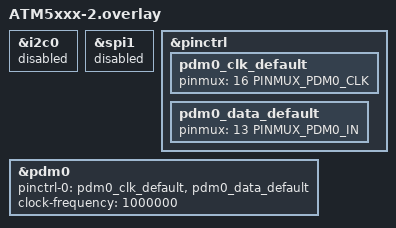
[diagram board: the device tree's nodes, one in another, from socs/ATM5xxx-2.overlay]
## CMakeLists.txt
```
# Copyright (c) 2026 Atmosic
#
# SPDX-License-Identifier: LicenseRef-Atmosic

cmake_minimum_required(VERSION 3.20.0)

find_package(Zephyr REQUIRED HINTS $ENV{ZEPHYR_BASE})
project(dmic_atm)

target_sources(app PRIVATE src/main.c)
```

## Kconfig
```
# Copyright (c) 2026 Atmosic
#
# SPDX-License-Identifier: LicenseRef-Atmosic

mainmenu "DMIC Sample"

source "Kconfig.zephyr"

choice SAMPLE_RATE_CHOICE
	prompt "PCM sample rate"
	default SAMPLE_RATE_16KHZ
	help
	  PCM sample rate requested from the dmic_atm driver. The driver
	  (openair/drivers/audio/dmic_atm.c, rate_to_sel()) only supports
	  8000 Hz and 16000 Hz.

config SAMPLE_RATE_8KHZ
	bool "8 kHz"

config SAMPLE_RATE_16KHZ
	bool "16 kHz"

endchoice

config SAMPLE_RATE_HZ
	int
	default 8000 if SAMPLE_RATE_8KHZ
	default 16000 if SAMPLE_RATE_16KHZ

config HW_CHANNEL_INDEX
	int "Hardware controller index"
	default 0
	help
	  Selects the PDM hardware controller index passed to
	  dmic_build_channel_map().  0 selects pdm0.

config DMIC_BENCH_DURATION_S
	int "Bench-test streaming duration (seconds)"
	default 2
	range 1 5
	help
	  How long to stream PDM audio before stopping and dumping the
	  captured samples. Kept short because the whole run is dumped
	  as hex over the console after stopping, and that dump is far
	  slower than the capture.
```

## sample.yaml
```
# Copyright (c) 2026 Atmosic
#
# SPDX-License-Identifier: LicenseRef-Atmosic

sample:
  name: DMIC
common:
  tags:
    - drivers
  sysbuild: true
  depends_on:
    - pdm
  harness: console
  harness_config:
    type: one_line
    regex:
      - 'PDM_CAPTURE_END captured=\d+ dropped=\d+'
tests:
  samples.drivers.audio.dmic.atm: {}
  samples.drivers.audio.dmic.atm.apx: &apx_base
    harness: pytest
    timeout: 600
    harness_config:
      pytest_root: ["pytest"]
      fixture: apx525
  samples.drivers.audio.dmic.atm.apx.rate_8khz:
    <<: *apx_base
    extra_configs:
      - CONFIG_SAMPLE_RATE_8KHZ=y
    harness_config:
      pytest_root: ["pytest"]
      fixture: apx525
      pytest_args:
        - "--apx-sweep-freqs-hz=250,500,750"
  samples.drivers.audio.dmic.atm.apx.bitclk_500khz:
    <<: *apx_base
    extra_args:
      - EXTRA_DTC_OVERLAY_FILE="bitclk_500khz.overlay"
    harness_config:
      pytest_root: ["pytest"]
      fixture: apx525
      pytest_args:
        - "--apx-bit-clk-freq-hz=500000"
        - "--apx-sweep-freqs-hz=500"
  samples.drivers.audio.dmic.atm.apx.bitclk_2mhz:
    <<: *apx_base
    extra_args:
      - EXTRA_DTC_OVERLAY_FILE="bitclk_2mhz.overlay"
    harness_config:
      pytest_root: ["pytest"]
      fixture: apx525
      pytest_args:
        - "--apx-bit-clk-freq-hz=2000000"
        - "--apx-sweep-freqs-hz=500,1000,1500"
  samples.drivers.audio.dmic.atm.apx.bitclk_4mhz:
    <<: *apx_base
    extra_args:
      - EXTRA_DTC_OVERLAY_FILE="bitclk_4mhz.overlay"
    harness_config:
      pytest_root: ["pytest"]
      fixture: apx525
      pytest_args:
        - "--apx-bit-clk-freq-hz=4000000"
        - "--apx-sweep-freqs-hz=500,1000,1500"
```

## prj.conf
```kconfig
# Copyright (c) 2026 Atmosic
#
# SPDX-License-Identifier: LicenseRef-Atmosic

CONFIG_AUDIO=y
CONFIG_AUDIO_DMIC=y
CONFIG_DMIC_ATM=y

CONFIG_LOG=y

# Send printk straight to the console (bypass the deferred log ring buffer)
# so the bench-test PCM hex dump is not silently truncated.
CONFIG_LOG_PRINTK=n
```

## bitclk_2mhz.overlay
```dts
/*
 * Copyright (c) 2026 Atmosic
 *
 * SPDX-License-Identifier: LicenseRef-Atmosic
 */

&pdm0 {
	clock-frequency = <2000000>;
};
```

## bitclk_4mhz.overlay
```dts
/*
 * Copyright (c) 2026 Atmosic
 *
 * SPDX-License-Identifier: LicenseRef-Atmosic
 */

&pdm0 {
	clock-frequency = <4000000>;
};
```

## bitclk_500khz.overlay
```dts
/*
 * Copyright (c) 2026 Atmosic
 *
 * SPDX-License-Identifier: LicenseRef-Atmosic
 */

&pdm0 {
	clock-frequency = <500000>;
};
```

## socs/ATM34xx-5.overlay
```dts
/*
 * Copyright (c) 2026 Atmosic
 *
 * SPDX-License-Identifier: LicenseRef-Atmosic
 */

&spi1 {
	status = "disabled";
};

&pinctrl {
	pdm0_clk_default: pdm0_clk_default {
		pinmux = <20 PINMUX_PDM0_CLK>;
	};

	pdm0_data_default: pdm0_data_default {
		pinmux = <21 PINMUX_PDM0_IN>;
	};
};

dmic_dev: &pdm0 {
	status = "okay";
	pinctrl-0 = <&pdm0_clk_default &pdm0_data_default>;
	pinctrl-names = "default";
	clock-frequency = <1000000>;
};
```

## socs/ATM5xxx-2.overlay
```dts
/*
 * Copyright (c) 2026 Atmosic
 *
 * SPDX-License-Identifier: LicenseRef-Atmosic
 */

&i2c0 {
	status = "disabled";
};

&spi1 {
	status = "disabled";
};

&pinctrl {
	pdm0_clk_default: pdm0_clk_default {
		pinmux = <16 PINMUX_PDM0_CLK>;
	};

	pdm0_data_default: pdm0_data_default {
		pinmux = <13 PINMUX_PDM0_IN>;
	};
};

dmic_dev: &pdm0 {
	status = "okay";
	pinctrl-0 = <&pdm0_clk_default &pdm0_data_default>;
	pinctrl-names = "default";
	clock-frequency = <1000000>;
};
```

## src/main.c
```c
/*
 * Copyright (c) Atmosic 2026
 *
 * SPDX-License-Identifier: LicenseRef-Atmosic
 */

#include <stdint.h>
#include <string.h>

#include <zephyr/kernel.h>
#include <zephyr/sys/util.h>
#include <zephyr/audio/dmic.h>

#include <zephyr/logging/log.h>

LOG_MODULE_REGISTER(dmic_sample);

#define MAX_SAMPLE_RATE  CONFIG_SAMPLE_RATE_HZ
#define SAMPLE_BIT_WIDTH 16
#define PDM_CTL_IDX      CONFIG_HW_CHANNEL_INDEX
#define BYTES_PER_SAMPLE (SAMPLE_BIT_WIDTH / 8)
#define READ_TIMEOUT     1000

#define PDM_HW_CHUNK_WORDS   16
#define PDM_HW_CHUNK_SAMPLES (PDM_HW_CHUNK_WORDS * 2)
#define PDM_BLOCK_SIZE       (PDM_HW_CHUNK_SAMPLES * BYTES_PER_SAMPLE)

#define MAX_BLOCK_SIZE PDM_BLOCK_SIZE
#define BLOCK_COUNT    4
K_MEM_SLAB_DEFINE_STATIC(mem_slab, MAX_BLOCK_SIZE, BLOCK_COUNT, 4);

#define DMIC_BENCH_WARMUP_MS 1000
#define MAX_READ_FAILURES    50

#define CAP_SAMPLES (MAX_SAMPLE_RATE * CONFIG_DMIC_BENCH_DURATION_S)
static int16_t capture_buf[CAP_SAMPLES];

int main(void)
{
	const struct device *dmic_dev = DEVICE_DT_GET(DT_NODELABEL(dmic_dev));

	if (!device_is_ready(dmic_dev)) {
		LOG_ERR("DMIC not ready");
		return 0;
	}

	struct pcm_stream_cfg stream = {
		.pcm_width = SAMPLE_BIT_WIDTH,
		.mem_slab = &mem_slab,
	};
	struct dmic_cfg cfg = {
		.io =
			{
				.min_pdm_clk_freq = 1000000,
				.max_pdm_clk_freq = 4000000,
				.min_pdm_clk_dc = 40,
				.max_pdm_clk_dc = 60,
			},
		.streams = &stream,
		.channel =
			{
				.req_num_streams = 1,
				.req_num_chan = 1,
				.req_chan_map_lo =
					dmic_build_channel_map(0, PDM_CTL_IDX, PDM_CHAN_LEFT),
			},
	};
	cfg.streams[0].pcm_rate = MAX_SAMPLE_RATE;
	cfg.streams[0].block_size = PDM_BLOCK_SIZE;

	int ret = dmic_configure(dmic_dev, &cfg);
	if (ret < 0) {
		LOG_ERR("Configure failed: %d", ret);
		return 0;
	}

	ret = dmic_trigger(dmic_dev, DMIC_TRIGGER_START);
	if (ret < 0) {
		LOG_ERR("START failed: %d", ret);
		return 0;
	}

	uint32_t pcm_rate = cfg.streams[0].pcm_rate;
	uint32_t warmup_samples = (DMIC_BENCH_WARMUP_MS * pcm_rate) / 1000U;
	uint32_t failures = 0;

	for (uint32_t warmed = 0; warmed < warmup_samples;) {
		void *buf;
		uint32_t size;
		ret = dmic_read(dmic_dev, 0, &buf, &size, READ_TIMEOUT);
		if (ret < 0) {
			if (++failures >= MAX_READ_FAILURES) {
				LOG_ERR("Warm-up abort: %u failures", failures);
				break;
			}
			continue;
		}
		failures = 0;
		k_mem_slab_free(&mem_slab, buf);
		warmed += PDM_HW_CHUNK_SAMPLES;
	}

	LOG_INF("Bench streaming started");

	uint32_t cap =
		MIN(CONFIG_DMIC_BENCH_DURATION_S * pcm_rate, (uint32_t)ARRAY_SIZE(capture_buf));
	uint32_t captured = 0, dropped = 0;
	failures = 0;

	while (captured < cap) {
		void *buf;
		uint32_t size;
		ret = dmic_read(dmic_dev, 0, &buf, &size, READ_TIMEOUT);
		if (ret < 0) {
			dropped++;
			if (++failures >= MAX_READ_FAILURES) {
				break;
			}
			continue;
		}
		failures = 0;
		memcpy(&capture_buf[captured], buf, PDM_HW_CHUNK_SAMPLES * sizeof(capture_buf[0]));
		k_mem_slab_free(&mem_slab, buf);
		captured += PDM_HW_CHUNK_SAMPLES;
	}

	dmic_trigger(dmic_dev, DMIC_TRIGGER_STOP);

	printk("PDM_CAPTURE_BEGIN rate=%u bits=%u samples=%u\n", pcm_rate, SAMPLE_BIT_WIDTH,
	       captured);
	for (uint32_t i = 0; i < captured; i++) {
		printk("%04x%c", (uint16_t)capture_buf[i],
		       (i % PDM_HW_CHUNK_SAMPLES == PDM_HW_CHUNK_SAMPLES - 1) ? '\n' : ' ');
	}
	if (captured % PDM_HW_CHUNK_SAMPLES != 0) {
		printk("\n");
	}
	printk("PDM_CAPTURE_END captured=%u dropped=%u\n", captured, dropped);

	return 0;
}
```
